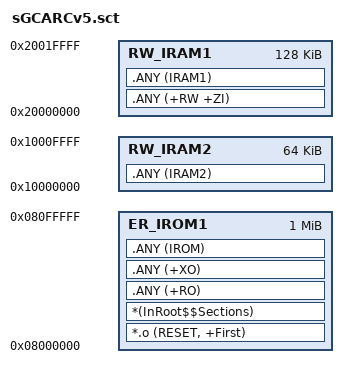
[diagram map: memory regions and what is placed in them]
; ******************************************************************
; *** Scatter-Loading Description File generated by Embedded IDE ***
; ******************************************************************
; by Sightseer. inHNIP9607Lab

LR_IROM1 0x08000000 0x00100000 {
	ER_IROM1 0x08000000 0x00100000 {
		*.o (RESET, +First) 
		*(InRoot$$Sections) 
		.ANY (+RO) 
		.ANY (+XO) 
		.ANY (IROM)
	}
	RW_IRAM1 0x20000000 0x00020000 {
		.ANY (+RW +ZI) 
		.ANY (IRAM1) 
	}
	RW_IRAM2 0x10000000 0x00010000 {
		;.ANY (+RW +ZI) 
		.ANY (IRAM2) 
	}
}

